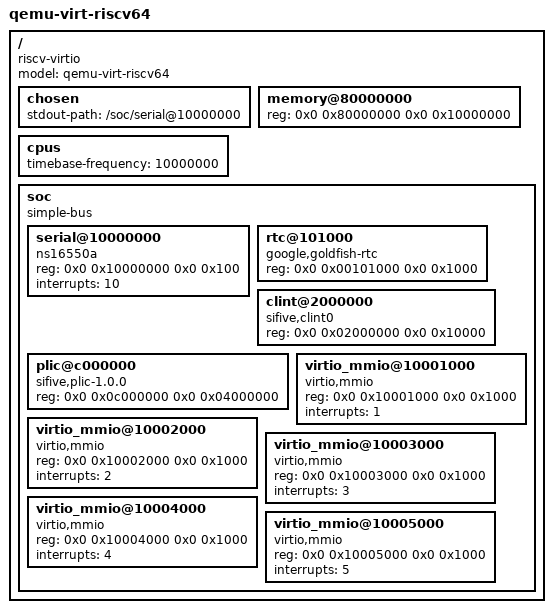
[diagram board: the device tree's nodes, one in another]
/dts-v1/;

/ {
    model = "qemu-virt-riscv64";
    compatible = "riscv-virtio", "qemu,virt";
    #address-cells = <2>;
    #size-cells = <2>;

    chosen {
        stdout-path = "/soc/serial@10000000";
    };

    memory@80000000 {
        device_type = "memory";
        reg = <0x0 0x80000000 0x0 0x10000000>;
    };

    cpus {
        #address-cells = <1>;
        #size-cells = <0>;
        timebase-frequency = <10000000>;
    };

    soc {
        #address-cells = <2>;
        #size-cells = <2>;
        compatible = "simple-bus";
        ranges;

        serial@10000000 {
            compatible = "ns16550a";
            reg = <0x0 0x10000000 0x0 0x100>;
            interrupts = <10>;
        };

        rtc@101000 {
            compatible = "google,goldfish-rtc";
            reg = <0x0 0x00101000 0x0 0x1000>;
        };

        clint@2000000 {
            compatible = "sifive,clint0";
            reg = <0x0 0x02000000 0x0 0x10000>;
        };

        plic@c000000 {
            compatible = "sifive,plic-1.0.0";
            reg = <0x0 0x0c000000 0x0 0x04000000>;
        };

        virtio_mmio@10001000 {
            compatible = "virtio,mmio";
            reg = <0x0 0x10001000 0x0 0x1000>;
            interrupts = <1>;
        };

        virtio_mmio@10002000 {
            compatible = "virtio,mmio";
            reg = <0x0 0x10002000 0x0 0x1000>;
            interrupts = <2>;
        };

        virtio_mmio@10003000 {
            compatible = "virtio,mmio";
            reg = <0x0 0x10003000 0x0 0x1000>;
            interrupts = <3>;
        };

        virtio_mmio@10004000 {
            compatible = "virtio,mmio";
            reg = <0x0 0x10004000 0x0 0x1000>;
            interrupts = <4>;
        };

        virtio_mmio@10005000 {
            compatible = "virtio,mmio";
            reg = <0x0 0x10005000 0x0 0x1000>;
            interrupts = <5>;
        };
    };
};
